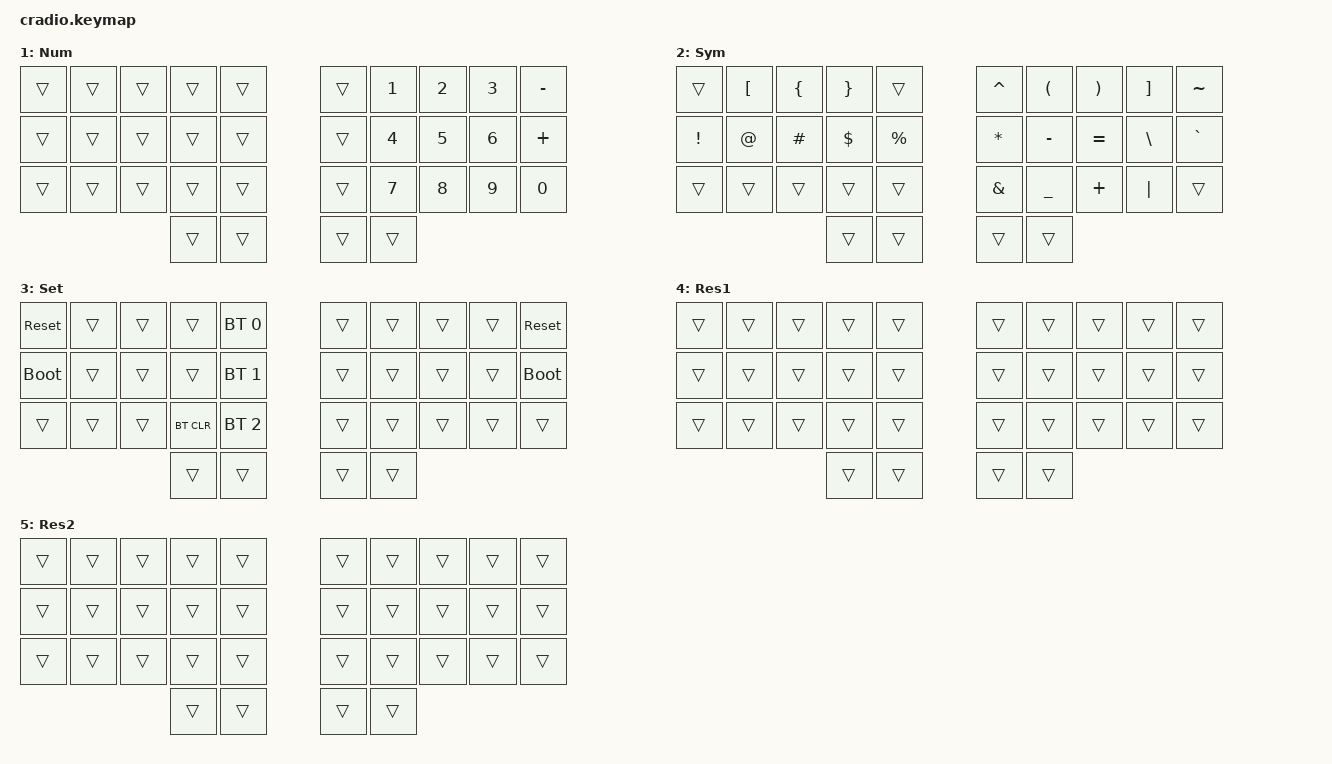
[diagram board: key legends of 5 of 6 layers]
// Copyright (c) 2022 The ZMK Contributors
// SPDX-License-Identifier: MIT

#include <behaviors.dtsi>
#include <dt-bindings/zmk/keys.h>
#include <dt-bindings/zmk/bt.h>

// Home row mods macro
// GACS/◆⎇⎈⇧ Gui, Alt, Ctrl, Shift
#define HRML(k1,k2,k3,k4) &ht LGUI k1  &ht LALT k2  &ht LCTRL k3  &ht LSHIFT k4
#define HRMR(k1,k2,k3,k4) &ht RSHIFT k1  &ht RCTRL k2  &ht RALT k3  &ht RGUI k4

#define DEF 0
#define NUM 1
#define SYM 2
#define SET 3

/ {
    behaviors {
        ht: hold_tap {
            compatible = "zmk,behavior-hold-tap";
            #binding-cells = <2>;
            flavor = "tap-preferred";
            tapping-term-ms = <220>;
            quick-tap-ms = <150>;
            require-prior-idle-ms = <100>;
            bindings = <&kp>, <&kp>;
        };
         td0: tap_dance_0 {
            compatible = "zmk,behavior-tap-dance";
            #binding-cells = <0>;
            tapping-term-ms = <200>;
            bindings = <&kp N1>, <&kp N2>, <&kp N3>;
         };
    };

    conditional_layers {
        compatible = "zmk,conditional-layers";
        tri_layer {
            if-layers = <1 2>;
            then-layer = <3>;
        };
    };

    keymap {
        compatible = "zmk,keymap";
        // Layer 0: Base - QWERTY + homerow mods ( GACS/◆⎇⎈⇧ )
        default_layer {
            display-name = "Base";
            bindings = <
        //╭──────────┬──────────┬──────────┬──────────┬──────────╮   ╭──────────┬──────────┬──────────┬──────────┬──────────╮
        //│  Q       │  W       │  E       │  R       │  T       │   │  Y       │  U       │  I       │  O       │  P       │
            &kp Q      &kp W      &kp E      &kp R      &kp T          &kp Y      &kp U      &kp I      &kp O      &kp P
        //├──────────┼──────────┼──────────┼──────────┼──────────┤   ├──────────┼──────────┼──────────┼──────────┼──────────┤
        //│  A       │  S       │  D       │  F       │  G       │   │  H       │  J       │  K       │  L       │ ; :      │
            HRML(A,        S,         D,         F)     &kp G          &kp H      HRMR(J,        K,         L,        SEMI)
        //├──────────┼──────────┼──────────┼──────────┼──────────┤   ├──────────┼──────────┼──────────┼──────────┼──────────┤
        //│  Z       │  X       │  C       │  V       │  B       │   │  N       │  M       │   , <    │   . >    │  / ?     │
            &kp Z      &kp X      &kp C      &kp V      &kp B          &kp N      &kp M      &kp COMMA  &kp DOT    &kp FSLH
        //╰──────────┴──────────┴──────────┼──────────┼──────────┤   ├──────────┼──────────┼──────────┴──────────┴──────────╯
                                        &lt NUM ENTER  &lt SET BSPC   &kp TAB  &lt SYM SPACE 
        //                                 ╰──────────┴──────────╯   ╰──────────┴──────────╯
            >;
        };
        
        // Layer 1: Numbers, and navigation
        right_layer {
            display-name = "Num";
            bindings = <
        //╭──────────┬──────────┬──────────┬──────────┬──────────╮   ╭──────────┬──────────┬──────────┬──────────┬──────────╮
        //│          │          │          │          │          │   │          │     1    │    2     │     3    │     -    │
             &trans     &trans     &trans     &trans     &trans         &trans     &kp N1     &kp N2      &kp N3   &kp MINUS
        //├──────────┼──────────┼──────────┼──────────┼──────────┤   ├──────────┼──────────┼──────────┼──────────┼──────────┤
        //│          │          │          │          │          │   │          │     4    │     5    │     6    │     +    │
             &trans     &trans     &trans     &trans     &trans         &trans     &kp N4      &kp 5      &kp 6    &kp PLUS
        //├──────────┼──────────┼──────────┼──────────┼──────────┤   ├──────────┼──────────┼──────────┼──────────┼──────────┤
        //│          │          │          │          │          │   │          │     7    │     8    │    9     │     0    │
             &trans     &trans     &trans     &trans     &trans         &trans     &kp N7     &kp N8     &kp N9     &kp N0
        //╰──────────┴──────────┴──────────┼──────────┼──────────┤   ├──────────┼──────────┼──────────┴──────────┴──────────╯
                                             &trans     &trans          &trans     &trans
        //                                 ╰──────────┴──────────╯   ╰──────────┴──────────╯
            >;
        };        
        // Layer 2: Symbols
        left_layer {
            display-name = "Sym";
            bindings = <
        //╭──────────┬──────────┬──────────┬──────────┬──────────╮   ╭──────────┬──────────┬──────────┬──────────┬──────────╮
        //│          │  [       │  {       │  }       │          │   │  ^       │  (       │  )       │  ]       │  ~       │
            &trans     &kp LBKT   &kp LBRC   &kp RBRC   &trans         &kp CARET  &kp LPAR   &kp RPAR   &kp RBKT   &kp TILDE
        //├──────────┼──────────┼──────────┼──────────┼──────────┤   ├──────────┼──────────┼──────────┼──────────┼──────────┤
        //│  !       │  @       │  #       │  $       │  %       │   │  *       │  -       │  =       │  \       │  `       │
            &kp EXCL   &kp AT     &kp HASH   &kp DLLR   &kp PRCNT      &kp ASTRK  &kp MINUS  &kp EQUAL  &kp BSLH   &kp GRAVE
        //├──────────┼──────────┼──────────┼──────────┼──────────┤   ├──────────┼──────────┼──────────┼──────────┼──────────┤
        //│          │          │          │          │          │   │  &       │  _       │  +       │  │       │          │
            &trans     &trans     &trans     &trans     &trans         &kp AMPS   &kp UNDER  &kp PLUS   &kp PIPE   &trans
        //╰──────────┴──────────┴──────────┼──────────┼──────────┤   ├──────────┼──────────┼──────────┴──────────┴──────────╯
                                             &trans     &trans         &trans     &trans
        //                                 ╰──────────┴──────────╯   ╰──────────┴──────────╯
            >;
        };

        // Layer 3: Settings: Bluetooth and reset
        tri_layer {
            display-name = "Set";
            bindings = <
        //╭──────────┬──────────┬──────────┬──────────┬──────────╮   ╭──────────┬──────────┬──────────┬──────────┬──────────╮
        //│ RESET    │          │          │          │PROFILE 0 │   │          │          │          │          │  RESET   │
           &sys_reset  &trans     &trans     &trans    &bt BT_SEL 0    &trans     &trans     &trans     &trans    &sys_reset
        //├──────────┼──────────┼──────────┼──────────┼──────────┤   ├──────────┼──────────┼──────────┼──────────┼──────────┤
        //│BOOTLOADER│          │          │          │PROFILE 1 │   │          │          │          │          │BOOTLOADER│
          &bootloader  &trans     &trans     &trans    &bt BT_SEL 1    &trans     &trans     &trans     &trans    &bootloader
        //├──────────┼──────────┼──────────┼──────────┼──────────┤   ├──────────┼──────────┼──────────┼──────────┼──────────┤
        //│          │          │          │ CLEAR BT │PROFILE 2 │   │          │          │          │          │          │
            &trans     &trans     &trans    &bt BT_CLR &bt BT_SEL 2    &trans     &trans     &trans     &trans     &trans
        //╰──────────┴──────────┴──────────┼──────────┼──────────┤   ├──────────┼──────────┼──────────┴──────────┴──────────╯
                                             &trans     &trans         &trans     &trans
        //                                 ╰──────────┴──────────╯   ╰──────────┴──────────╯
            >;
        };

        // Layer 4: 
        reserved_01 {
            display-name = "Res1";
            bindings = <
        //╭──────────┬──────────┬──────────┬──────────┬──────────╮   ╭──────────┬──────────┬──────────┬──────────┬──────────╮
        //│          │          │          │          │          │   │          │          │          │          │          │
             &trans     &trans     &trans     &trans     &trans         &trans     &trans     &trans     &trans     &trans
        //├──────────┼──────────┼──────────┼──────────┼──────────┤   ├──────────┼──────────┼──────────┼──────────┼──────────┤
        //│          │          │          │          │          │   │          │          │          │          │          │
             &trans     &trans     &trans     &trans     &trans         &trans     &trans     &trans     &trans     &trans
        //├──────────┼──────────┼──────────┼──────────┼──────────┤   ├──────────┼──────────┼──────────┼──────────┼──────────┤
        //│          │          │          │          │          │   │          │          │          │          │          │
             &trans     &trans     &trans     &trans     &trans         &trans     &trans     &trans     &trans     &trans
        //╰──────────┴──────────┴──────────┼──────────┼──────────┤   ├──────────┼──────────┼──────────┴──────────┴──────────╯
                                              &trans     &trans         &trans     &trans
        //                                 ╰──────────┴──────────╯   ╰──────────┴──────────╯
            >;
        };

        // Layer 5: 
        reserved_02 {
            display-name = "Res2";
            bindings = <
        //╭──────────┬──────────┬──────────┬──────────┬──────────╮   ╭──────────┬──────────┬──────────┬──────────┬──────────╮
        //│          │          │          │          │          │   │          │          │          │          │          │
             &trans     &trans     &trans     &trans     &trans         &trans     &trans     &trans     &trans     &trans
        //├──────────┼──────────┼──────────┼──────────┼──────────┤   ├──────────┼──────────┼──────────┼──────────┼──────────┤
        //│          │          │          │          │          │   │          │          │          │          │          │
             &trans     &trans     &trans     &trans     &trans         &trans     &trans     &trans     &trans     &trans
        //├──────────┼──────────┼──────────┼──────────┼──────────┤   ├──────────┼──────────┼──────────┼──────────┼──────────┤
        //│          │          │          │          │          │   │          │          │          │          │          │
             &trans     &trans     &trans     &trans     &trans         &trans     &trans     &trans     &trans     &trans
        //╰──────────┴──────────┴──────────┼──────────┼──────────┤   ├──────────┼──────────┼──────────┴──────────┴──────────╯
                                              &trans     &trans         &trans     &trans
        //                                 ╰──────────┴──────────╯   ╰──────────┴──────────╯
            >;
        };
    };
};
